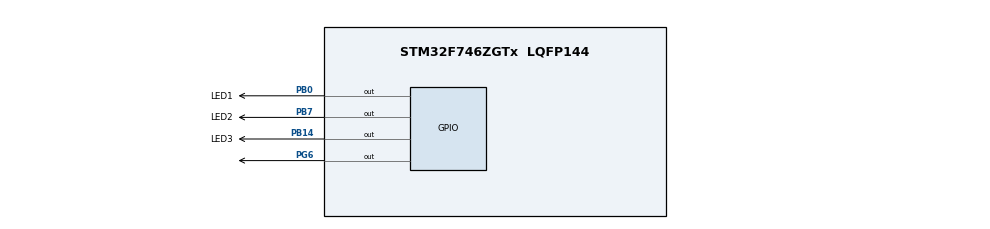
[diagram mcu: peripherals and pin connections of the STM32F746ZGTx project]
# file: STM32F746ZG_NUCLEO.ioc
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Mcu.Family=STM32F7
Mcu.Name=STM32F746ZGTx
Mcu.Package=LQFP144
NVIC.PriorityGroup=NVIC_PRIORITYGROUP_4
PB0.GPIO_Label=LED1
PB0.Signal=GPIO_Output
PB14.GPIO_Label=LED3
PB14.Signal=GPIO_Output
PB7.GPIO_Label=LED2
PB7.Signal=GPIO_Output
PD8.Signal=USART3_TX
PD9.Signal=USART3_RX
PG6.Signal=GPIO_Output
PH0/OSC_IN.Mode=HSE-External-Clock-Source
PH0/OSC_IN.Signal=RCC_OSC_IN
PH1/OSC_OUT.Mode=HSE-External-Clock-Source
PH1/OSC_OUT.Signal=RCC_OSC_OUT
ProjectManager.HeapSize=0x200
ProjectManager.StackSize=0x400
ProjectManager.TargetToolchain=EWARM V8.32
RCC.HSE_VALUE=8000000
RCC.HSI_VALUE=16000000
RCC.LSE_VALUE=32768
RCC.PLLM=4
RCC.USBFreq_Value=384000000
RCC.VCOOutputFreq_Value=768000000
STMicroelectronics.X-CUBE-COMPONENTS.1.4.1.ComponentsCcLEDJjLED=GPIO
VP_STMicroelectronics.X-CUBE-COMPONENTS_VS_LEDJjComponents_1.0.0_1.4.1.Mode=LEDJjComponents
board=custom

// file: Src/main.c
/* USER CODE BEGIN Header */
/**
  ******************************************************************************
  * @file           : main.c
  * @brief          : Main program body
  ******************************************************************************
  * @attention
  *
  * <h2><center>&copy; Copyright (c) 2021 STMicroelectronics.
  * All rights reserved.</center></h2>
  *
  * This software component is licensed by ST under Ultimate Liberty license
  * SLA0044, the "License"; You may not use this file except in compliance with
  * the License. You may obtain a copy of the License at:
  *                             www.st.com/SLA0044
  *
  ******************************************************************************
  */
/* USER CODE END Header */
#include "main.h"

/* USER CODE BEGIN Includes */
#include "led.h"
/* USER CODE END Includes */

void SystemClock_Config(void);
static void MX_GPIO_Init(void);

int main(void)
{

  /* MCU Configuration--------------------------------------------------------*/

  /* Reset of all peripherals, Initializes the Flash interface and the Systick. */
  HAL_Init();

  /* Configure the system clock */
  SystemClock_Config();

  /* Initialize all configured peripherals */
  MX_GPIO_Init();

  /* Infinite loop */
  /* USER CODE BEGIN WHILE */
  while (1)
  {
    BSP_LED_Toggle(LED1);
    BSP_LED_Toggle(LED2);
    BSP_LED_Toggle(LED3);
    HAL_Delay(100);
    /* USER CODE END WHILE */

  }
}

void SystemClock_Config(void)
{
  RCC_OscInitTypeDef RCC_OscInitStruct = {0};
  RCC_ClkInitTypeDef RCC_ClkInitStruct = {0};

  /** Configure the main internal regulator output voltage
  */
  __HAL_RCC_PWR_CLK_ENABLE();
  __HAL_PWR_VOLTAGESCALING_CONFIG(PWR_REGULATOR_VOLTAGE_SCALE3);
  /** Initializes the RCC Oscillators according to the specified parameters
  * in the RCC_OscInitTypeDef structure.
  */
  RCC_OscInitStruct.OscillatorType = RCC_OSCILLATORTYPE_HSI;
  RCC_OscInitStruct.HSIState = RCC_HSI_ON;
  RCC_OscInitStruct.HSICalibrationValue = RCC_HSICALIBRATION_DEFAULT;
  RCC_OscInitStruct.PLL.PLLState = RCC_PLL_NONE;
  if (HAL_RCC_OscConfig(&RCC_OscInitStruct) != HAL_OK)
  {
    Error_Handler();
  }
  /** Initializes the CPU, AHB and APB buses clocks
  */
  RCC_ClkInitStruct.ClockType = RCC_CLOCKTYPE_HCLK|RCC_CLOCKTYPE_SYSCLK
                              |RCC_CLOCKTYPE_PCLK1|RCC_CLOCKTYPE_PCLK2;
  RCC_ClkInitStruct.SYSCLKSource = RCC_SYSCLKSOURCE_HSI;
  RCC_ClkInitStruct.AHBCLKDivider = RCC_SYSCLK_DIV1;
  RCC_ClkInitStruct.APB1CLKDivider = RCC_HCLK_DIV1;
  RCC_ClkInitStruct.APB2CLKDivider = RCC_HCLK_DIV1;

  if (HAL_RCC_ClockConfig(&RCC_ClkInitStruct, FLASH_LATENCY_0) != HAL_OK)
  {
    Error_Handler();
  }
}

static void MX_GPIO_Init(void)
{
  GPIO_InitTypeDef GPIO_InitStruct = {0};

  /* GPIO Ports Clock Enable */
  __HAL_RCC_GPIOH_CLK_ENABLE();
  __HAL_RCC_GPIOB_CLK_ENABLE();
  __HAL_RCC_GPIOD_CLK_ENABLE();
  __HAL_RCC_GPIOG_CLK_ENABLE();

  /*Configure GPIO pin Output Level */
  HAL_GPIO_WritePin(GPIOB, LED1_Pin|LED3_Pin|LED2_Pin, GPIO_PIN_RESET);

  /*Configure GPIO pin Output Level */
  HAL_GPIO_WritePin(GPIOG, GPIO_PIN_6, GPIO_PIN_RESET);

  /*Configure GPIO pins : LED1_Pin LED3_Pin LED2_Pin */
  GPIO_InitStruct.Pin = LED1_Pin|LED3_Pin|LED2_Pin;
  GPIO_InitStruct.Mode = GPIO_MODE_OUTPUT_PP;
  GPIO_InitStruct.Pull = GPIO_NOPULL;
  GPIO_InitStruct.Speed = GPIO_SPEED_FREQ_LOW;
  HAL_GPIO_Init(GPIOB, &GPIO_InitStruct);

  /*Configure GPIO pins : PD8 PD9 */
  GPIO_InitStruct.Pin = GPIO_PIN_8|GPIO_PIN_9;
  GPIO_InitStruct.Mode = GPIO_MODE_AF_PP;
  GPIO_InitStruct.Pull = GPIO_NOPULL;
  GPIO_InitStruct.Speed = GPIO_SPEED_FREQ_VERY_HIGH;
  GPIO_InitStruct.Alternate = GPIO_AF7_USART3;
  HAL_GPIO_Init(GPIOD, &GPIO_InitStruct);

  /*Configure GPIO pin : PG6 */
  GPIO_InitStruct.Pin = GPIO_PIN_6;
  GPIO_InitStruct.Mode = GPIO_MODE_OUTPUT_PP;
  GPIO_InitStruct.Pull = GPIO_NOPULL;
  GPIO_InitStruct.Speed = GPIO_SPEED_FREQ_LOW;
  HAL_GPIO_Init(GPIOG, &GPIO_InitStruct);

}

void Error_Handler(void)
{
  __disable_irq();
  while (1)
  {
  }
}

/************************ (C) COPYRIGHT STMicroelectronics *****END OF FILE****/
